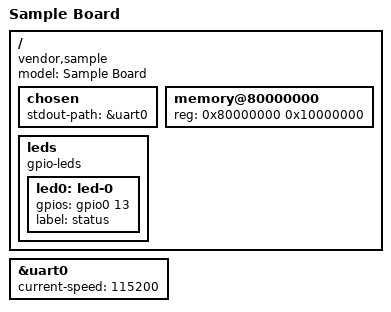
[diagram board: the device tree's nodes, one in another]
/dts-v1/;

#include "base.dtsi"

/* A sample. */
/ {
	model = "Sample Board";
	compatible = "vendor,sample";
	#address-cells = <1>;
	#size-cells = <1>;

	chosen {
		stdout-path = &uart0;
	};

	memory@80000000 {
		device_type = "memory";
		reg = <0x80000000 0x10000000>;
	};

	leds {
		compatible = "gpio-leds";

		led0: led-0 {
			gpios = <&gpio0 13 0>;
			label = "status";
		};
	};
};

&uart0 {
	status = "okay";
	current-speed = <115200>;
};
